AUTOSAR XML (schema 4-2-1)
package /RootP_ASWC_M415
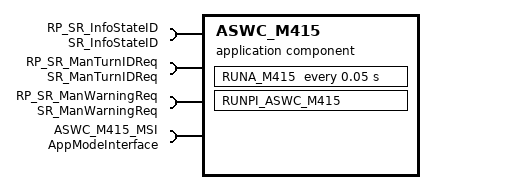
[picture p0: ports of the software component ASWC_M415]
  application sw component type ASWC_M415
    provide/require port PRP_SR_EtatClignotant: nonqueued-receiver-com-spec{data-element=EtatClignotant, enable-update=0, handle-data-status=1, handle-never-received=0, init-value=CONST_t_EtatClignotant_0:0}, provided-required-interface=SR_EtatClignotant
    provide/require port PRP_SR_EtatFeuxDettresse: nonqueued-receiver-com-spec{data-element=EtatFeuxDetresse, enable-update=0, handle-data-status=1, handle-never-received=0, init-value=CONST_tLOG_0:0}, provided-required-interface=SR_EtatFeuxDettresse
    provide/require port PRP_SR_TypeCmdID: nonqueued-receiver-com-spec{data-element=TypeCmdID, enable-update=0, handle-data-status=1, handle-never-received=0, init-value=CONST_t_TypeCmdID_0:0}, provided-required-interface=SR_TypeCmdID
    4 x require port:
      RP_SR_InfoStateID: required-interface=SR_InfoStateID
        required-com-specs:
          data-element=FlagImpulsEnd, enable-update=0, handle-data-status=1, handle-never-received=0, init-value=CONST_tLOG_0:0
          data-element=StateID, enable-update=0, handle-data-status=1, handle-never-received=0, init-value=CONST_tLOG_0:0
      RP_SR_ManTurnIDReq: nonqueued-receiver-com-spec{data-element=ManTurnIDReq, enable-update=0, handle-data-status=1, handle-never-received=0, init-value=CONST_t_IndicatorDirection_0:0}, required-interface=SR_ManTurnIDReq
      RP_SR_ManWarningReq: nonqueued-receiver-com-spec{data-element=ManWarningReq, enable-update=0, handle-data-status=1, handle-never-received=0, init-value=CONST_tLOG_0:0}, required-interface=SR_ManWarningReq
      ASWC_M415_MSI: required-interface=AppModeInterface
    behavior IB_ASWC_M415: data-type-mapping=ApplicationModeMapping, handle-termination-and-restart=NO-SUPPORT
      ar-typed-per-instance-memorys:
        data PIM_M415_ManTurnIDReq_Prec: type=t_IndicatorDirection, init-value=CONST_PIM_M415_ManTurnIDReq_Prec_t_IndicatorDirection_cNoID:0
        data PIM_M415_ManWarningReq_Prec: type=tLOG, init-value=CONST_tLOG_0:0
        data PIM_M415_WarningMem: type=tLOG, init-value=CONST_tLOG_0:0
      timing event RUNA_M415_Cyclic: start-on-event=RUNA_M415, period=0.05
        disabled-mode:
          ASWC_M415_MSI.AppMode.APP_WAKEUP
          ASWC_M415_MSI.AppMode.APP_OFF
          ASWC_M415_MSI.AppMode.APP_SYNC_INIT
          ASWC_M415_MSI.AppMode.APP_CONFIG
      swc mode switch event RUNPI_ASWC_M415_ENTRY: start-on-event=RUNPI_ASWC_M415, activation=ON-ENTRY, mode=ASWC_M415_MSI.AppMode.APP_WAKEUP
      runnable RUNA_M415
        data-read-access:
          7 x access:
            dra_RP_SR_InfoStateID_FlagImpulsEnd: accessed-variable=RP_SR_InfoStateID.FlagImpulsEnd
            dra_RP_SR_ManTurnIDReq_ManTurnIDReq: accessed-variable=RP_SR_ManTurnIDReq.ManTurnIDReq
            dra_RP_SR_ManWarningReq_ManWarningReq: accessed-variable=RP_SR_ManWarningReq.ManWarningReq
            dra_RP_SR_InfoStateID_StateID: accessed-variable=RP_SR_InfoStateID.StateID
            dra_PRP_SR_EtatClignotant_EtatClignotant: accessed-variable=PRP_SR_EtatClignotant.EtatClignotant
            dra_PRP_SR_EtatFeuxDettresse_EtatFeuxDetresse: accessed-variable=PRP_SR_EtatFeuxDettresse.EtatFeuxDetresse
            dra_PRP_SR_TypeCmdID_TypeCmdID: accessed-variable=PRP_SR_TypeCmdID.TypeCmdID
        data-write-access:
          access dwa_PRP_SR_EtatClignotant_EtatClignotant: accessed-variable=PRP_SR_EtatClignotant.EtatClignotant
          access dwa_PRP_SR_EtatFeuxDettresse_EtatFeuxDetresse: accessed-variable=PRP_SR_EtatFeuxDettresse.EtatFeuxDetresse
          access dwa_PRP_SR_TypeCmdID_TypeCmdID: accessed-variable=PRP_SR_TypeCmdID.TypeCmdID
      runnable RUNPI_ASWC_M415
package /RootP_Implementatation
  swc implementation Implementatation_ASWC_M415: programming-language=C, sw-version=1.0.0, vendor-id=1, behavior=IB_ASWC_M415
    code-descriptors:
      code SRC: artifact-descriptors=autosar-engineering-object={short-label=EngObject, category=SWSRC}
    resource consumption Resources
